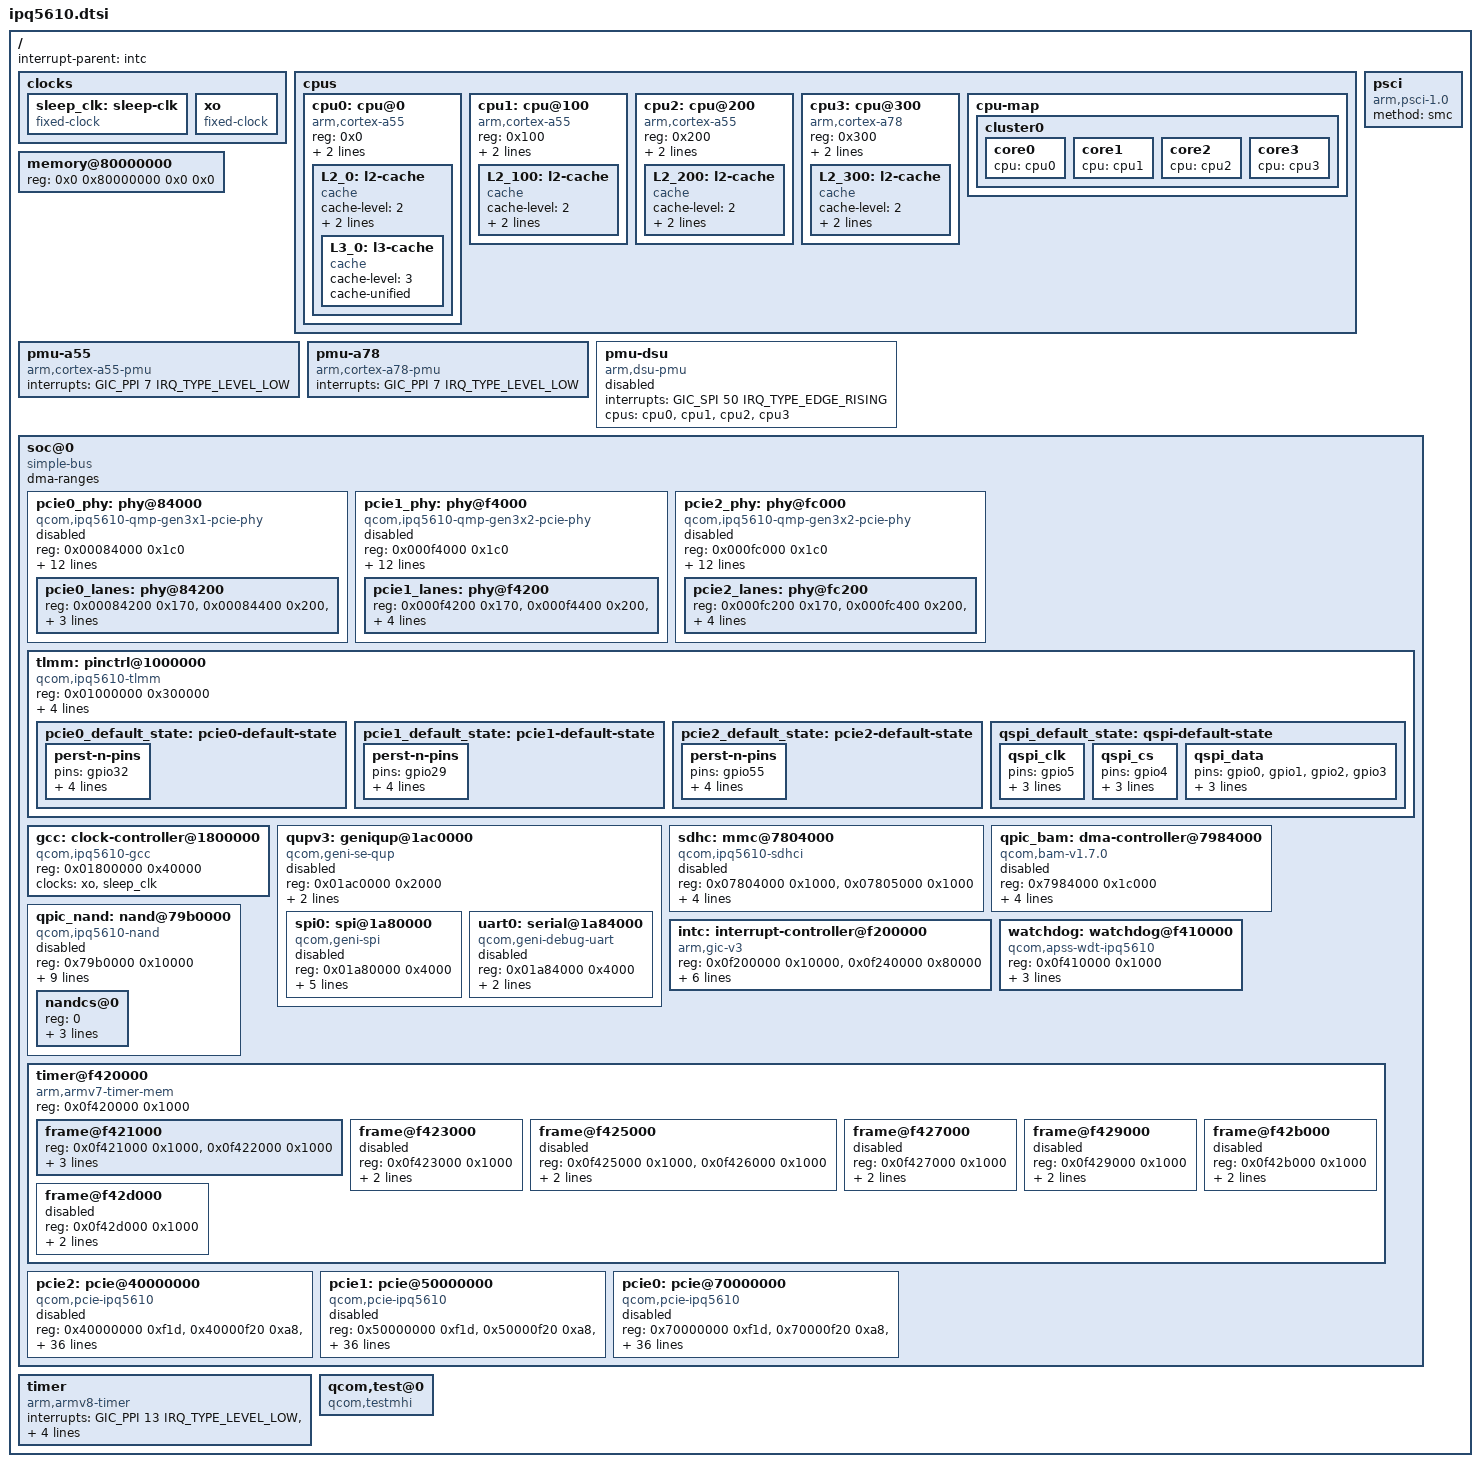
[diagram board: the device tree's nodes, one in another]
// SPDX-License-Identifier: (GPL-2.0+ OR BSD-3-Clause)
/*
 * IPQ5610 device tree source
 *
 * Copyright (c) 2020-2021 The Linux Foundation. All rights reserved.
 * Copyright (c) Qualcomm Technologies, Inc. and/or its subsidiaries.
 */

#include <dt-bindings/clock/qcom,ipq5610-gcc.h>
#include <dt-bindings/reset/qcom,ipq5610-gcc.h>
#include <dt-bindings/interrupt-controller/arm-gic.h>
#include <dt-bindings/gpio/gpio.h>

/ {
	#address-cells = <2>;
	#size-cells = <2>;
	interrupt-parent = <&intc>;

	clocks {
		sleep_clk: sleep-clk {
			compatible = "fixed-clock";
			#clock-cells = <0>;
		};

		xo: xo {
			compatible = "fixed-clock";
			#clock-cells = <0>;
		};
	};

	cpus: cpus {
		#address-cells = <1>;
		#size-cells = <0>;

		cpu0: cpu@0 {
			device_type = "cpu";
			compatible = "arm,cortex-a55";
			reg = <0x0>;
			enable-method = "psci";
			next-level-cache = <&L2_0>;
			L2_0: l2-cache {
				compatible = "cache";
				cache-level = <2>;
				cache-unified;
				next-level-cache = <&L3_0>;
				L3_0: l3-cache {
					compatible = "cache";
					cache-level = <3>;
					cache-unified;
				};
			};
		};

		cpu1: cpu@100 {
			device_type = "cpu";
			compatible = "arm,cortex-a55";
			reg = <0x100>;
			enable-method = "psci";
			next-level-cache = <&L2_100>;
			L2_100: l2-cache {
				compatible = "cache";
				cache-level = <2>;
				cache-unified;
				next-level-cache = <&L3_0>;
			};
		};

		cpu2: cpu@200 {
			device_type = "cpu";
			compatible = "arm,cortex-a55";
			reg = <0x200>;
			enable-method = "psci";
			next-level-cache = <&L2_200>;
			L2_200: l2-cache {
				compatible = "cache";
				cache-level = <2>;
				cache-unified;
				next-level-cache = <&L3_0>;
			};
		};

		cpu3: cpu@300 {
			device_type = "cpu";
			compatible = "arm,cortex-a78";
			reg = <0x300>;
			enable-method = "psci";
			next-level-cache = <&L2_300>;
			L2_300: l2-cache {
				compatible = "cache";
				cache-level = <2>;
				cache-unified;
				next-level-cache = <&L3_0>;
			};
		};

		cpu-map {
			cluster0 {
				core0 {
					cpu = <&cpu0>;
				};

				core1 {
					cpu = <&cpu1>;
				};

				core2 {
					cpu = <&cpu2>;
				};

				core3 {
					cpu = <&cpu3>;
				};

			};

		};
	};

	memory@80000000 {
		device_type = "memory";
		/* We expect the bootloader to fill in the size */
		reg = <0x0 0x80000000 0x0 0x0>;
	};

	pmu-a55 {
		compatible = "arm,cortex-a55-pmu";
		interrupts = <GIC_PPI 7 IRQ_TYPE_LEVEL_LOW>;
	};

	pmu-a78 {
		compatible = "arm,cortex-a78-pmu";
		interrupts = <GIC_PPI 7 IRQ_TYPE_LEVEL_LOW>;
	};

	pmu-dsu {
		compatible = "arm,dsu-pmu";
		interrupts = <GIC_SPI 50 IRQ_TYPE_EDGE_RISING>;
		cpus = <&cpu0>, <&cpu1>, <&cpu2>, <&cpu3>;
		status = "disabled";
	};

	psci {
		compatible = "arm,psci-1.0";
		method = "smc";
	};

	soc@0 {
		compatible = "simple-bus";
		#address-cells = <1>;
		#size-cells = <1>;
		ranges = <0 0 0 0xffffffff>;
		dma-ranges;

		pcie0_phy: phy@84000 {
			compatible = "qcom,ipq5610-qmp-gen3x1-pcie-phy",
				     "qcom,ipq9574-qmp-gen3x1-pcie-phy";
			reg = <0x00084000 0x1c0>; /* Serdes PLL */
			#address-cells = <1>;
			#size-cells = <1>;
			ranges;

			clocks = <&gcc GCC_PCIE0_AUX_CLK>,
				 <&gcc GCC_PCIE0_AHB_CLK>,
				 <&gcc GCC_ANOC_PCIE0_1LANE_M_CLK>,
				 <&gcc GCC_ANOC_PCIE0_1LANE_S_CLK>;
			clock-names = "aux", "cfg_ahb", "anoc_lane", "snoc_lane";

			assigned-clocks = <&gcc GCC_PCIE0_AUX_CLK>,
					  <&gcc GCC_PCIE0_AHB_CLK>,
					  <&gcc GCC_ANOC_PCIE0_1LANE_M_CLK>,
					  <&gcc GCC_ANOC_PCIE0_1LANE_S_CLK>;
			assigned-clock-rates = <20000000>,
					       <100000000>,
					       <200000000>,
					       <200000000>;

			resets = <&gcc GCC_PCIE0_PHY_BCR>,
				 <&gcc GCC_PCIE0PHY_PHY_BCR>;
			reset-names = "phy", "common";

			status = "disabled";

			pcie0_lanes: phy@84200 {
				reg = <0x00084200 0x170>, /* Serdes Tx0 */
				      <0x00084400 0x200>, /* Serdes Rx0 */
				      <0x00084600 0x1f0>, /* PCS: Lane0, COM, PCIE */
				      <0x00084a00 0x0f4>; /* pcs_misc */

				#phy-cells = <0>;

				clocks = <&gcc GCC_PCIE0_PIPE_CLK>;
				clock-names = "pipe0";
				clock-output-names = "gcc_pcie0_pipe_clk_src";
				#clock-cells = <0>;
			};
		};

		pcie1_phy: phy@f4000 {
			compatible = "qcom,ipq5610-qmp-gen3x2-pcie-phy",
				     "qcom,ipq9574-qmp-gen3x2-pcie-phy";
			reg = <0x000f4000 0x1c0>; /* Serdes PLL */
			#address-cells = <1>;
			#size-cells = <1>;
			ranges;

			clocks = <&gcc GCC_PCIE1_AUX_CLK>,
				 <&gcc GCC_PCIE1_AHB_CLK>,
				 <&gcc GCC_ANOC_PCIE1_2LANE_M_CLK>,
				 <&gcc GCC_ANOC_PCIE1_2LANE_S_CLK>;
			clock-names = "aux", "cfg_ahb", "anoc_lane", "snoc_lane";

			assigned-clocks = <&gcc GCC_PCIE1_AUX_CLK>,
					  <&gcc GCC_PCIE1_AHB_CLK>,
					  <&gcc GCC_ANOC_PCIE1_2LANE_M_CLK>,
					  <&gcc GCC_ANOC_PCIE1_2LANE_S_CLK>;
			assigned-clock-rates = <20000000>,
					       <100000000>,
					       <266666666>,
					       <200000000>;

			resets = <&gcc GCC_PCIE1_PHY_BCR>,
				 <&gcc GCC_PCIE1PHY_PHY_BCR>;
			reset-names = "phy", "common";

			status = "disabled";

			pcie1_lanes: phy@f4200 {
				reg = <0x000f4200 0x170>, /* Serdes Tx0 */
				      <0x000f4400 0x200>, /* Serdes Rx0 */
				      <0x000f4a00 0x1f0>, /* PCS: Lane0, COM, PCIE */
				      <0x000f4600 0x170>, /* Serdes Tx1 */
				      <0x000f4800 0x200>, /* Serdes Rx1 */
				      <0x000f4e00 0x0f4>; /* pcs_misc */

				#phy-cells = <0>;

				clocks = <&gcc GCC_PCIE1_PIPE_CLK>;
				clock-names = "pipe0";
				clock-output-names = "gcc_pcie1_pipe_clk_src";
				#clock-cells = <0>;
			};
		};

		pcie2_phy: phy@fc000 {
			compatible = "qcom,ipq5610-qmp-gen3x2-pcie-phy",
				     "qcom,ipq9574-qmp-gen3x2-pcie-phy";
			reg = <0x000fc000 0x1c0>; /* Serdes PLL PCIE_2_CFG_QSERDES_PLL_QSERDES_PLL_G3X2_QMP_PLL */
			#address-cells = <1>;
			#size-cells = <1>;
			ranges;

			clocks = <&gcc GCC_PCIE2_AUX_CLK>,
				 <&gcc GCC_PCIE2_AHB_CLK>,
				 <&gcc GCC_ANOC_PCIE2_2LANE_M_CLK>,
				 <&gcc GCC_ANOC_PCIE2_2LANE_S_CLK>;
			clock-names = "aux", "cfg_ahb", "anoc_lane", "snoc_lane";

			assigned-clocks = <&gcc GCC_PCIE2_AUX_CLK>,
					  <&gcc GCC_PCIE2_AHB_CLK>,
					  <&gcc GCC_ANOC_PCIE2_2LANE_M_CLK>,
					  <&gcc GCC_ANOC_PCIE2_2LANE_S_CLK>;
			assigned-clock-rates = <20000000>,
					       <100000000>,
					       <266666666>,
					       <240000000>;

			resets = <&gcc GCC_PCIE2_PHY_BCR>,
				 <&gcc GCC_PCIE2PHY_PHY_BCR>;
			reset-names = "phy", "common";

			status = "disabled";

			pcie2_lanes: phy@fc200 {
				reg = <0x000fc200 0x170>, /* Serdes Tx0 */
				      <0x000fc400 0x200>, /* Serdes Rx0 */
				      <0x000fca00 0x1f0>, /* PCS: Lane0, COM, PCIE */
				      <0x000fc600 0x170>, /* Serdes Tx1 */
				      <0x000fc800 0x200>, /* Serdes Rx1 */
				      <0x000fce00 0x0f4>; /* pcs_misc */

				#phy-cells = <0>;

				clocks = <&gcc GCC_PCIE2_PIPE_CLK>;
				clock-names = "pipe0";
				clock-output-names = "gcc_pcie2_pipe_clk_src";
				#clock-cells = <0>;
			};
		};

		tlmm: pinctrl@1000000 {
			compatible = "qcom,ipq5610-tlmm";
			reg = <0x01000000 0x300000>;
			interrupts = <GIC_SPI 85 IRQ_TYPE_LEVEL_HIGH>;
			gpio-controller;
			#gpio-cells = <2>;
			gpio-ranges = <&tlmm 0 0 62>;
			interrupt-controller;
			#interrupt-cells = <2>;

			pcie0_default_state: pcie0-default-state {
				perst-n-pins {
					pins = "gpio32";
					function = "gpio";
					drive-strength = <2>;
					bias-pull-down;
					output-low;
				};
			};

			pcie1_default_state: pcie1-default-state {
				perst-n-pins {
					pins = "gpio29";
					function = "gpio";
					drive-strength = <2>;
					bias-pull-down;
					output-low;
				};
			};

			pcie2_default_state: pcie2-default-state {
				perst-n-pins {
					pins = "gpio55";
					function = "gpio";
					drive-strength = <2>;
					bias-pull-down;
					output-low;
				};
			};

			qspi_default_state: qspi-default-state {
				qspi_clk {
					pins = "gpio5";
					function = "qspi_clk";
					drive-strength = <8>;
					bias-pull-down;
				};

				qspi_cs {
					pins = "gpio4";
					function = "qspi_cs_n";
					drive-strength = <8>;
					bias-pull-up;
				};

				qspi_data {
					pins = "gpio0", "gpio1", "gpio2", "gpio3";
					function = "qspi_data";
					drive-strength = <8>;
					bias-pull-down;
				};
			};
		};

		gcc: clock-controller@1800000 {
			compatible = "qcom,ipq5610-gcc";
			reg = <0x01800000 0x40000>;

			clocks = <&xo>,
				 <&sleep_clk>;
			#clock-cells = <1>;
			#reset-cells = <1>;
			#power-domain-cells = <1>;
		};

		qupv3: geniqup@1ac0000 {
			compatible = "qcom,geni-se-qup";
			reg = <0x01ac0000 0x2000>;
			clocks = <&gcc GCC_QUPV3_AHB_MST_CLK>,
				 <&gcc GCC_QUPV3_AHB_SLV_CLK>;
			clock-names = "m-ahb", "s-ahb";
			ranges;
			#address-cells = <1>;
			#size-cells = <1>;

			status = "disabled";

			spi0: spi@1a80000 {
				compatible = "qcom,geni-spi";
				reg = <0x01a80000 0x4000>;
				clocks = <&gcc GCC_QUPV3_WRAP_SE0_CLK>;
				clock-names = "se";
				interrupts = <GIC_SPI 379 IRQ_TYPE_LEVEL_HIGH>;
				assigned-clocks = <&gcc GCC_QUPV3_WRAP_SE0_CLK>;
				assigned-clock-rates = <50000000>;
				/* Use common SE TX FIFO depth configuration */
				qup-tx-fifo-depth = <0x20>;
				status = "disabled";
			};

			uart0: serial@1a84000 {
				compatible = "qcom,geni-debug-uart";
				reg = <0x01a84000 0x4000>;
				clocks = <&gcc GCC_QUPV3_WRAP_SE1_CLK>;
				clock-names = "se";
				interrupts = <GIC_SPI 380 IRQ_TYPE_LEVEL_HIGH>;
				status = "disabled";
			};
		};

		sdhc: mmc@7804000 {
			compatible = "qcom,ipq5610-sdhci", "qcom,sdhci-msm-v5";
			reg = <0x07804000 0x1000>, <0x07805000 0x1000>;

			interrupts = <GIC_SPI 123 IRQ_TYPE_LEVEL_HIGH>,
				     <GIC_SPI 126 IRQ_TYPE_LEVEL_HIGH>;
			interrupt-names = "hc_irq", "pwr_irq";

			clocks = <&gcc GCC_SDCC1_AHB_CLK>,
				 <&gcc GCC_SDCC1_APPS_CLK>,
				 <&xo>;
			clock-names = "iface", "core", "xo";

			status = "disabled";
		};

		qpic_bam: dma-controller@7984000 {
			compatible = "qcom,bam-v1.7.0";
			reg = <0x7984000 0x1c000>;
			interrupts = <GIC_SPI 114 IRQ_TYPE_LEVEL_HIGH>;
			clocks = <&gcc GCC_QPIC_AHB_CLK>;
			clock-names = "bam_clk";
			#dma-cells = <1>;
			qcom,ee = <0>;
			qcom,bam-lite;
			status = "disabled";
		};

		qpic_nand: nand@79b0000 {
			compatible = "qcom,ipq5610-nand";
			reg = <0x79b0000 0x10000>;
			#address-cells = <1>;
			#size-cells = <0>;
			clocks = <&gcc GCC_QPIC_CLK>,
				 <&gcc GCC_QPIC_AHB_CLK>,
				 <&gcc GCC_QPIC_IO_MACRO_CLK>;
			clock-names = "core", "aon", "io_macro";

			dmas = <&qpic_bam 0>,
			       <&qpic_bam 1>,
			       <&qpic_bam 2>,
			       <&qpic_bam 3>;
			dma-names = "tx", "rx", "cmd", "sts";

			qcom,io_macro_max_clk = <400000000>;
			qcom,io_macro_clk_rates = <24000000 100000000 200000000 \
						   320000000 400000000>;

			pinctrl-0 = <&qspi_default_state>;
			pinctrl-names = "default";

			status = "disabled";
			nandcs@0 {
				reg = <0>;
				#address-cells = <1>;
				#size-cells = <1>;

				nand-ecc-strength = <8>;
				nand-ecc-step-size = <512>;
				nand-bus-width = <8>;
			};
		};

		intc: interrupt-controller@f200000 {
			compatible = "arm,gic-v3";
			reg = <0x0f200000 0x10000>,
			      <0x0f240000 0x80000>;
			#interrupt-cells = <0x3>;
			interrupt-controller;
			#redistributor-regions = <1>;
			redistributor-stride = <0x0 0x20000>;
			interrupts = <GIC_PPI 9 IRQ_TYPE_LEVEL_HIGH>;
			mbi-ranges = <800 96>;
			msi-controller;
		};

		watchdog: watchdog@f410000 {
			compatible = "qcom,apss-wdt-ipq5610", "qcom,kpss-wdt";
			reg = <0x0f410000 0x1000>;
			interrupts = <GIC_SPI 0 IRQ_TYPE_EDGE_RISING>;
			clocks = <&sleep_clk>;
			timeout-sec = <30>;
		};

		timer@f420000 {
			compatible = "arm,armv7-timer-mem";
			reg = <0x0f420000 0x1000>;
			#address-cells = <1>;
			#size-cells = <1>;
			ranges;

			frame@f421000 {
				reg = <0x0f421000 0x1000>,
				      <0x0f422000 0x1000>;
				interrupts = <GIC_SPI 8 IRQ_TYPE_LEVEL_HIGH>,
					     <GIC_SPI 6 IRQ_TYPE_LEVEL_HIGH>;
				frame-number = <0>;
			};

			frame@f423000 {
				reg = <0x0f423000 0x1000>;
				interrupts = <GIC_SPI 9 IRQ_TYPE_LEVEL_HIGH>;
				frame-number = <1>;
				status = "disabled";
			};

			frame@f425000 {
				reg = <0x0f425000 0x1000>,
				      <0x0f426000 0x1000>;
				interrupts = <GIC_SPI 10 IRQ_TYPE_LEVEL_HIGH>;
				frame-number = <2>;
				status = "disabled";
			};

			frame@f427000 {
				reg = <0x0f427000 0x1000>;
				interrupts = <GIC_SPI 11 IRQ_TYPE_LEVEL_HIGH>;
				frame-number = <3>;
				status = "disabled";
			};

			frame@f429000 {
				reg = <0x0f429000 0x1000>;
				interrupts = <GIC_SPI 12 IRQ_TYPE_LEVEL_HIGH>;
				frame-number = <4>;
				status = "disabled";
			};

			frame@f42b000 {
				reg = <0x0f42b000 0x1000>;
				interrupts = <GIC_SPI 13 IRQ_TYPE_LEVEL_HIGH>;
				frame-number = <5>;
				status = "disabled";
			};

			frame@f42d000 {
				reg = <0x0f42d000 0x1000>;
				interrupts = <GIC_SPI 14 IRQ_TYPE_LEVEL_HIGH>;
				frame-number = <6>;
				status = "disabled";
			};
		};

		pcie2: pcie@40000000 {
			compatible = "qcom,pcie-ipq5610";
			reg =  <0x40000000 0xf1d>,
			       <0x40000f20 0xa8>,
			       <0x40001000 0x1000>,
			       <0x000f8000 0x3000>,
			       <0x40100000 0x1000>;
			reg-names = "dbi", "elbi", "atu", "parf", "config";
			device_type = "pci";
			linux,pci-domain = <2>;
			bus-range = <0x00 0xff>;
			num-lanes = <2>;
			#address-cells = <3>;
			#size-cells = <2>;

			ranges = <0x81000000 0 0x40200000 0x40200000 0 0x00100000>,   /* downstream I/O */
				 <0x82000000 0 0x40300000 0x40300000 0 0x0fd00000>; /* non-prefetchable memory */

			#interrupt-cells = <1>;
			interrupt-map-mask = <0 0 0 0x7>;
			interrupt-map = <0 0 0 1 &intc 0 474 IRQ_TYPE_LEVEL_HIGH>, /* int_a */
					<0 0 0 2 &intc 0 475 IRQ_TYPE_LEVEL_HIGH>, /* int_b */
					<0 0 0 3 &intc 0 476 IRQ_TYPE_LEVEL_HIGH>, /* int_c */
					<0 0 0 4 &intc 0 477 IRQ_TYPE_LEVEL_HIGH>; /* int_d */

			interrupts = <GIC_SPI 473 IRQ_TYPE_LEVEL_HIGH>;
			interrupt-names = "global_irq";

			clocks = <&gcc GCC_PCIE2_AXI_M_CLK>,
				 <&gcc GCC_PCIE2_AXI_S_CLK>,
				 <&gcc GCC_PCIE2_AHB_CLK>,
				 <&gcc GCC_PCIE2_AUX_CLK>,
				 <&gcc GCC_PCIE2_AXI_S_BRIDGE_CLK>,
				 <&gcc GCC_PCIE2_RCHNG_CLK>;

			clock-names = "axi_m",
				      "axi_s",
				      "ahb",
				      "aux",
				      "axi_bridge",
				      "rchng";

			assigned-clocks = <&gcc GCC_PCIE2_AUX_CLK>,
					  <&gcc GCC_PCIE2_AXI_M_CLK>,
					  <&gcc GCC_PCIE2_AXI_S_BRIDGE_CLK>,
					  <&gcc GCC_PCIE2_AXI_S_CLK>,
					  <&gcc GCC_PCIE2_RCHNG_CLK>;

			assigned-clock-rates = <20000000>,
					       <266666666>,
					       <200000000>,
					       <200000000>,
					       <100000000>;

			resets = <&gcc GCC_PCIE2_PIPE_ARES>,
				 <&gcc GCC_PCIE2_CORE_STICKY_RESET>,
				 <&gcc GCC_PCIE2_AXI_M_ARES>,
				 <&gcc GCC_PCIE2_AXI_S_ARES>,
				 <&gcc GCC_PCIE2_AXI_M_STICKY_RESET>,
				 <&gcc GCC_PCIE2_AXI_S_STICKY_RESET>,
				 <&gcc GCC_PCIE2_AHB_ARES>,
				 <&gcc GCC_PCIE2_AUX_ARES>;

			reset-names = "pipe",
				      "sticky",
				      "axi_m",
				      "axi_s",
				      "axi_m_sticky",
				      "axi_s_sticky",
				      "ahb",
				      "aux";

			msi-parent = <&intc>;

			pinctrl-0 = <&pcie2_default_state>;
			pinctrl-names = "default";

			phys = <&pcie2_lanes>;
			phy-names = "pciephy";

			status = "disabled";
		};

		pcie1: pcie@50000000 {
			compatible = "qcom,pcie-ipq5610";
			reg =  <0x50000000 0xf1d>,
			       <0x50000f20 0xa8>,
			       <0x50001000 0x1000>,
			       <0x000f0000 0x3000>,
			       <0x50100000 0x1000>;
			reg-names = "dbi", "elbi", "atu", "parf", "config";
			device_type = "pci";
			linux,pci-domain = <1>;
			bus-range = <0x00 0xff>;
			num-lanes = <2>;
			#address-cells = <3>;
			#size-cells = <2>;

			ranges = <0x81000000 0 0x50200000 0x50200000 0 0x00100000>,   /* downstream I/O */
				 <0x82000000 0 0x50300000 0x50300000 0 0x0fd00000>; /* non-prefetchable memory */

			#interrupt-cells = <1>;
			interrupt-map-mask = <0 0 0 0x7>;
			interrupt-map = <0 0 0 1 &intc 0 459 IRQ_TYPE_LEVEL_HIGH>, /* int_a */
					<0 0 0 2 &intc 0 460 IRQ_TYPE_LEVEL_HIGH>, /* int_b */
					<0 0 0 3 &intc 0 461 IRQ_TYPE_LEVEL_HIGH>, /* int_c */
					<0 0 0 4 &intc 0 462 IRQ_TYPE_LEVEL_HIGH>; /* int_d */

			interrupts = <GIC_SPI 458 IRQ_TYPE_LEVEL_HIGH>;
			interrupt-names = "global_irq";

			clocks = <&gcc GCC_PCIE1_AXI_M_CLK>,
				 <&gcc GCC_PCIE1_AXI_S_CLK>,
				 <&gcc GCC_PCIE1_AHB_CLK>,
				 <&gcc GCC_PCIE1_AUX_CLK>,
				 <&gcc GCC_PCIE1_AXI_S_BRIDGE_CLK>,
				 <&gcc GCC_PCIE1_RCHNG_CLK>;

			clock-names = "axi_m",
				      "axi_s",
				      "ahb",
				      "aux",
				      "axi_bridge",
				      "rchng";

			assigned-clocks = <&gcc GCC_PCIE1_AUX_CLK>,
					  <&gcc GCC_PCIE1_AXI_M_CLK>,
					  <&gcc GCC_PCIE1_AXI_S_BRIDGE_CLK>,
					  <&gcc GCC_PCIE1_AXI_S_CLK>,
					  <&gcc GCC_PCIE1_RCHNG_CLK>;

			assigned-clock-rates = <20000000>,
					       <266666666>,
					       <200000000>,
					       <200000000>,
					       <100000000>;

			resets = <&gcc GCC_PCIE1_PIPE_ARES>,
				 <&gcc GCC_PCIE1_CORE_STICKY_RESET>,
				 <&gcc GCC_PCIE1_AXI_M_ARES>,
				 <&gcc GCC_PCIE1_AXI_S_ARES>,
				 <&gcc GCC_PCIE1_AXI_M_STICKY_RESET>,
				 <&gcc GCC_PCIE1_AXI_S_STICKY_RESET>,
				 <&gcc GCC_PCIE1_AHB_ARES>,
				 <&gcc GCC_PCIE1_AUX_ARES>;

			reset-names = "pipe",
				      "sticky",
				      "axi_m",
				      "axi_s",
				      "axi_m_sticky",
				      "axi_s_sticky",
				      "ahb",
				      "aux";

			msi-parent = <&intc>;

			pinctrl-0 = <&pcie1_default_state>;
			pinctrl-names = "default";

			phys = <&pcie1_lanes>;
			phy-names = "pciephy";

			status = "disabled";
		};

		pcie0: pcie@70000000 {
			compatible = "qcom,pcie-ipq5610";
			reg =  <0x70000000 0xf1d>,
			       <0x70000f20 0xa8>,
			       <0x70001000 0x1000>,
			       <0x00080000 0x3000>,
			       <0x70100000 0x1000>;
			reg-names = "dbi", "elbi", "atu", "parf", "config";
			device_type = "pci";
			linux,pci-domain = <0>;
			bus-range = <0x00 0xff>;
			num-lanes = <1>;
			#address-cells = <3>;
			#size-cells = <2>;

			ranges = <0x81000000 0 0x70200000 0x70200000 0 0x00100000>,   /* downstream I/O */
				 <0x82000000 0 0x70300000 0x70300000 0 0x0fd00000>; /* non-prefetchable memory */

			#interrupt-cells = <1>;
			interrupt-map-mask = <0 0 0 0x7>;
			interrupt-map = <0 0 0 1 &intc 0 444 IRQ_TYPE_LEVEL_HIGH>, /* int_a */
					<0 0 0 2 &intc 0 445 IRQ_TYPE_LEVEL_HIGH>, /* int_b */
					<0 0 0 3 &intc 0 446 IRQ_TYPE_LEVEL_HIGH>, /* int_c */
					<0 0 0 4 &intc 0 447 IRQ_TYPE_LEVEL_HIGH>; /* int_d */

			interrupts = <GIC_SPI 443 IRQ_TYPE_LEVEL_HIGH>;
			interrupt-names = "global_irq";

			clocks = <&gcc GCC_PCIE0_AXI_M_CLK>,
				 <&gcc GCC_PCIE0_AXI_S_CLK>,
				 <&gcc GCC_PCIE0_AHB_CLK>,
				 <&gcc GCC_PCIE0_AUX_CLK>,
				 <&gcc GCC_PCIE0_AXI_S_BRIDGE_CLK>,
				 <&gcc GCC_PCIE0_RCHNG_CLK>;

			clock-names = "axi_m",
				      "axi_s",
				      "ahb",
				      "aux",
				      "axi_bridge",
				      "rchng";

			assigned-clocks = <&gcc GCC_PCIE0_AUX_CLK>,
					  <&gcc GCC_PCIE0_AXI_M_CLK>,
					  <&gcc GCC_PCIE0_AXI_S_BRIDGE_CLK>,
					  <&gcc GCC_PCIE0_AXI_S_CLK>,
					  <&gcc GCC_PCIE0_RCHNG_CLK>;

			assigned-clock-rates = <20000000>,
					       <200000000>,
					       <200000000>,
					       <200000000>,
					       <100000000>;

			resets = <&gcc GCC_PCIE0_PIPE_ARES>,
				 <&gcc GCC_PCIE0_CORE_STICKY_RESET>,
				 <&gcc GCC_PCIE0_AXI_M_ARES>,
				 <&gcc GCC_PCIE0_AXI_S_ARES>,
				 <&gcc GCC_PCIE0_AXI_M_STICKY_RESET>,
				 <&gcc GCC_PCIE0_AXI_S_STICKY_RESET>,
				 <&gcc GCC_PCIE0_AHB_ARES>,
				 <&gcc GCC_PCIE0_AUX_ARES>;

			reset-names = "pipe",
				      "sticky",
				      "axi_m",
				      "axi_s",
				      "axi_m_sticky",
				      "axi_s_sticky",
				      "ahb",
				      "aux";

			msi-parent = <&intc>;

			pinctrl-0 = <&pcie0_default_state>;
			pinctrl-names = "default";

			phys = <&pcie0_lanes>;
			phy-names = "pciephy";

			status = "disabled";
		};

	};

	timer {
		compatible = "arm,armv8-timer";
		interrupts = <GIC_PPI 13 IRQ_TYPE_LEVEL_LOW>,
			     <GIC_PPI 14 IRQ_TYPE_LEVEL_LOW>,
			     <GIC_PPI 11 IRQ_TYPE_LEVEL_LOW>,
			     <GIC_PPI 10 IRQ_TYPE_LEVEL_LOW>,
			     <GIC_PPI 12 IRQ_TYPE_LEVEL_LOW>;
	};


	qcom,test@0 {
		compatible = "qcom,testmhi";
	};
};

